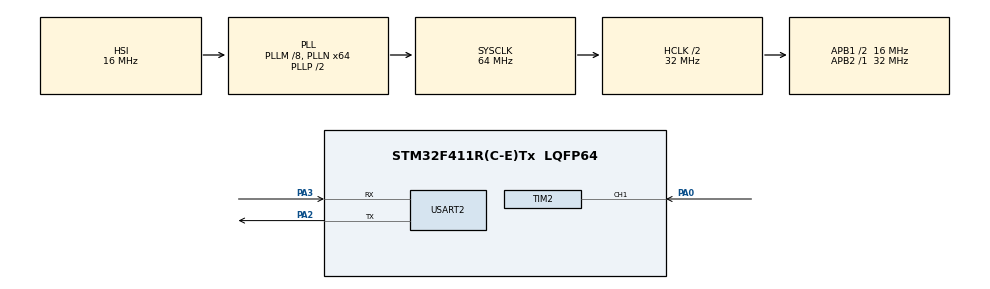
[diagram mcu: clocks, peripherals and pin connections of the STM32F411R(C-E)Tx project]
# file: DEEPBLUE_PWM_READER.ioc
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Mcu.Family=STM32F4
Mcu.Name=STM32F411R(C-E)Tx
Mcu.Package=LQFP64
NVIC.PriorityGroup=NVIC_PRIORITYGROUP_4
NVIC.TIM2_IRQn=true\:0\:0\:false\:false\:true\:true\:true\:true
PA0-WKUP.Signal=S_TIM2_CH1_ETR
PA13.Mode=Serial_Wire
PA13.Signal=SYS_JTMS-SWDIO
PA14.Mode=Serial_Wire
PA14.Signal=SYS_JTCK-SWCLK
PA2.Mode=Asynchronous
PA2.Signal=USART2_TX
PA3.Mode=Asynchronous
PA3.Signal=USART2_RX
ProjectManager.HeapSize=0x200
ProjectManager.StackSize=0x400
ProjectManager.TargetToolchain=STM32CubeIDE
RCC.48MHZClocksFreq_Value=32000000
RCC.AHBCLKDivider=RCC_SYSCLK_DIV2
RCC.AHBFreq_Value=32000000
RCC.APB1CLKDivider=RCC_HCLK_DIV2
RCC.APB1Freq_Value=16000000
RCC.APB1TimFreq_Value=32000000
RCC.APB2Freq_Value=32000000
RCC.APB2TimFreq_Value=32000000
RCC.CortexFreq_Value=32000000
RCC.HCLKFreq_Value=32000000
RCC.HSE_VALUE=25000000
RCC.HSI_VALUE=16000000
RCC.LSE_VALUE=32768
RCC.PLLM=8
RCC.PLLN=64
RCC.SYSCLKFreq_VALUE=64000000
RCC.SYSCLKSource=RCC_SYSCLKSOURCE_PLLCLK
RCC.VCOOutputFreq_Value=128000000
SH.S_TIM2_CH1_ETR.0=TIM2_CH1,PWM_Input_1
TIM2.Period=65536-1
TIM2.Prescaler=8-1
USART2.Parity=PARITY_NONE
USART2.VirtualMode=VM_ASYNC
board=custom

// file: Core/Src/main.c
/* USER CODE BEGIN Header */
/**
 ******************************************************************************
 * @file           : main.c
 * @brief          : Main program body
 ******************************************************************************
 * @attention
 *
 * Copyright (c) 2025 STMicroelectronics.
 * All rights reserved.
 *
 * This software is licensed under terms that can be found in the LICENSE file
 * in the root directory of this software component.
 * If no LICENSE file comes with this software, it is provided AS-IS.
 *
 ******************************************************************************
 */
/* USER CODE END Header */
#include "main.h"

/* USER CODE BEGIN Includes */
#include <string.h>
#include <stdio.h>
/* USER CODE END Includes */

/* USER CODE BEGIN PD */
#define F_CLK  4000000UL
/* USER CODE END PD */

TIM_HandleTypeDef htim2;

UART_HandleTypeDef huart2;

/* USER CODE BEGIN PV */
uint32_t Frequency, CycleTime = 0;
float Duty = 0.0;
char buff[] = "Frequency: %d, Duty: %d \n";
char str[100];
/* USER CODE END PV */

void SystemClock_Config(void);
static void MX_GPIO_Init(void);
static void MX_TIM2_Init(void);
static void MX_USART2_UART_Init(void);

int main(void)
{

  /* MCU Configuration--------------------------------------------------------*/

  /* Reset of all peripherals, Initializes the Flash interface and the Systick. */
  HAL_Init();

  /* Configure the system clock */
  SystemClock_Config();

  /* Initialize all configured peripherals */
  MX_GPIO_Init();
  MX_TIM2_Init();
  MX_USART2_UART_Init();
  /* USER CODE BEGIN 2 */
	HAL_TIM_IC_Start_IT(&htim2, TIM_CHANNEL_1);
	HAL_TIM_IC_Start(&htim2, TIM_CHANNEL_2);
  /* USER CODE END 2 */

  /* Infinite loop */
  /* USER CODE BEGIN WHILE */
	while (1) {
		sprintf(str, buff, Frequency, (int) (Duty));

		if (HAL_UART_Transmit(&huart2, (uint8_t*) str, strlen(str), 100)
				!= HAL_OK) {
			Error_Handler();
		}
		HAL_Delay(500);
    /* USER CODE END WHILE */

	}
}

void SystemClock_Config(void)
{
  RCC_OscInitTypeDef RCC_OscInitStruct = {0};
  RCC_ClkInitTypeDef RCC_ClkInitStruct = {0};

  /** Configure the main internal regulator output voltage
  */
  __HAL_RCC_PWR_CLK_ENABLE();
  __HAL_PWR_VOLTAGESCALING_CONFIG(PWR_REGULATOR_VOLTAGE_SCALE1);

  /** Initializes the RCC Oscillators according to the specified parameters
  * in the RCC_OscInitTypeDef structure.
  */
  RCC_OscInitStruct.OscillatorType = RCC_OSCILLATORTYPE_HSI;
  RCC_OscInitStruct.HSIState = RCC_HSI_ON;
  RCC_OscInitStruct.HSICalibrationValue = RCC_HSICALIBRATION_DEFAULT;
  RCC_OscInitStruct.PLL.PLLState = RCC_PLL_ON;
  RCC_OscInitStruct.PLL.PLLSource = RCC_PLLSOURCE_HSI;
  RCC_OscInitStruct.PLL.PLLM = 8;
  RCC_OscInitStruct.PLL.PLLN = 64;
  RCC_OscInitStruct.PLL.PLLP = RCC_PLLP_DIV2;
  RCC_OscInitStruct.PLL.PLLQ = 4;
  if (HAL_RCC_OscConfig(&RCC_OscInitStruct) != HAL_OK)
  {
    Error_Handler();
  }

  /** Initializes the CPU, AHB and APB buses clocks
  */
  RCC_ClkInitStruct.ClockType = RCC_CLOCKTYPE_HCLK|RCC_CLOCKTYPE_SYSCLK
                              |RCC_CLOCKTYPE_PCLK1|RCC_CLOCKTYPE_PCLK2;
  RCC_ClkInitStruct.SYSCLKSource = RCC_SYSCLKSOURCE_PLLCLK;
  RCC_ClkInitStruct.AHBCLKDivider = RCC_SYSCLK_DIV2;
  RCC_ClkInitStruct.APB1CLKDivider = RCC_HCLK_DIV2;
  RCC_ClkInitStruct.APB2CLKDivider = RCC_HCLK_DIV1;

  if (HAL_RCC_ClockConfig(&RCC_ClkInitStruct, FLASH_LATENCY_1) != HAL_OK)
  {
    Error_Handler();
  }
}

static void MX_TIM2_Init(void)
{

  TIM_SlaveConfigTypeDef sSlaveConfig = {0};
  TIM_IC_InitTypeDef sConfigIC = {0};
  TIM_MasterConfigTypeDef sMasterConfig = {0};

  htim2.Instance = TIM2;
  htim2.Init.Prescaler = 8-1;
  htim2.Init.CounterMode = TIM_COUNTERMODE_UP;
  htim2.Init.Period = 65536-1;
  htim2.Init.ClockDivision = TIM_CLOCKDIVISION_DIV1;
  htim2.Init.AutoReloadPreload = TIM_AUTORELOAD_PRELOAD_DISABLE;
  if (HAL_TIM_IC_Init(&htim2) != HAL_OK)
  {
    Error_Handler();
  }
  sSlaveConfig.SlaveMode = TIM_SLAVEMODE_RESET;
  sSlaveConfig.InputTrigger = TIM_TS_TI1FP1;
  sSlaveConfig.TriggerPolarity = TIM_INPUTCHANNELPOLARITY_RISING;
  sSlaveConfig.TriggerPrescaler = TIM_ICPSC_DIV1;
  sSlaveConfig.TriggerFilter = 0;
  if (HAL_TIM_SlaveConfigSynchro(&htim2, &sSlaveConfig) != HAL_OK)
  {
    Error_Handler();
  }
  sConfigIC.ICPolarity = TIM_INPUTCHANNELPOLARITY_RISING;
  sConfigIC.ICSelection = TIM_ICSELECTION_DIRECTTI;
  sConfigIC.ICPrescaler = TIM_ICPSC_DIV1;
  sConfigIC.ICFilter = 0;
  if (HAL_TIM_IC_ConfigChannel(&htim2, &sConfigIC, TIM_CHANNEL_1) != HAL_OK)
  {
    Error_Handler();
  }
  sConfigIC.ICPolarity = TIM_INPUTCHANNELPOLARITY_FALLING;
  sConfigIC.ICSelection = TIM_ICSELECTION_INDIRECTTI;
  if (HAL_TIM_IC_ConfigChannel(&htim2, &sConfigIC, TIM_CHANNEL_2) != HAL_OK)
  {
    Error_Handler();
  }
  sMasterConfig.MasterOutputTrigger = TIM_TRGO_RESET;
  sMasterConfig.MasterSlaveMode = TIM_MASTERSLAVEMODE_DISABLE;
  if (HAL_TIMEx_MasterConfigSynchronization(&htim2, &sMasterConfig) != HAL_OK)
  {
    Error_Handler();
  }

}

static void MX_USART2_UART_Init(void)
{

  huart2.Instance = USART2;
  huart2.Init.BaudRate = 115200;
  huart2.Init.WordLength = UART_WORDLENGTH_8B;
  huart2.Init.StopBits = UART_STOPBITS_1;
  huart2.Init.Parity = UART_PARITY_NONE;
  huart2.Init.Mode = UART_MODE_TX_RX;
  huart2.Init.HwFlowCtl = UART_HWCONTROL_NONE;
  huart2.Init.OverSampling = UART_OVERSAMPLING_16;
  if (HAL_UART_Init(&huart2) != HAL_OK)
  {
    Error_Handler();
  }

}

static void MX_GPIO_Init(void)
{

  /* GPIO Ports Clock Enable */
  __HAL_RCC_GPIOA_CLK_ENABLE();

}

/* USER CODE BEGIN 4 */
void HAL_TIM_IC_CaptureCallback(TIM_HandleTypeDef *htim) {
	if (htim->Instance == TIM2) {
		CycleTime = HAL_TIM_ReadCapturedValue(htim, TIM_CHANNEL_1);
		if (CycleTime != 0) {
			Duty =
					((HAL_TIM_ReadCapturedValue(htim, TIM_CHANNEL_2))
							* 100.0) / CycleTime;
			Frequency = (F_CLK / CycleTime);
		}
	}
}
/* USER CODE END 4 */

void Error_Handler(void)
{
	__disable_irq();
	while (1) {
	}
}
